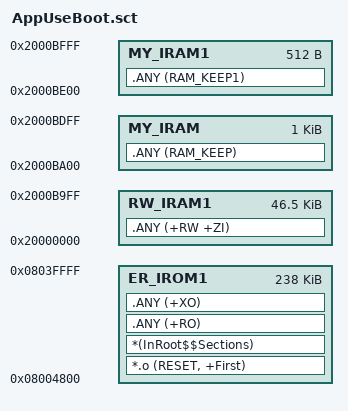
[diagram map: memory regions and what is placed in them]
; *************************************************************
; *** Scatter-Loading Description File generated by uVision ***
; *************************************************************

LR_IROM1 0x08004800 0x0003B800  {    ; load region size_region
  ER_IROM1 0x08004800 0x0003B800  {  ; load address = execution address
   *.o (RESET, +First)
   *(InRoot$$Sections)
   .ANY (+RO)
   .ANY (+XO)
  }
  RW_IRAM1 0x20000000 0x0000BA00  {  ; RW data
   .ANY (+RW +ZI)
  }

   MY_IRAM  0x2000BA00 0x00000400  {  ; RW data
   .ANY (RAM_KEEP)
  }
  
  MY_IRAM1 0x2000BE00 0x00000200  {  ; RW data
   .ANY (RAM_KEEP1)
  }
}

